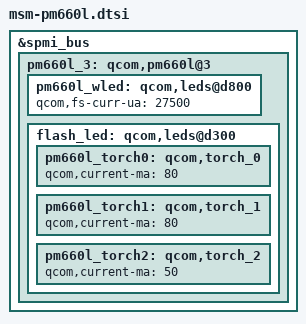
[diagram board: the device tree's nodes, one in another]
/* Copyright (c) 2016-2017, The Linux Foundation. All rights reserved.
 *
 * This program is free software; you can redistribute it and/or modify
 * it under the terms of the GNU General Public License version 2 and
 * only version 2 as published by the Free Software Foundation.
 *
 * This program is distributed in the hope that it will be useful,
 * but WITHOUT ANY WARRANTY; without even the implied warranty of
 * MERCHANTABILITY or FITNESS FOR A PARTICULAR PURPOSE.  See the
 * GNU General Public License for more details.
 */

&spmi_bus {
	pm660l_3: qcom,pm660l@3 {
		pm660l_wled: qcom,leds@d800 {
			qcom,fs-curr-ua = <27500>;
		};
		flash_led: qcom,leds@d300 {
			pm660l_torch0: qcom,torch_0 {
				qcom,current-ma = <80>;
			};

			pm660l_torch1: qcom,torch_1 {
				qcom,current-ma = <80>;
			};

			pm660l_torch2: qcom,torch_2 {
				qcom,current-ma = <50>;
			};

		};


	};
};
